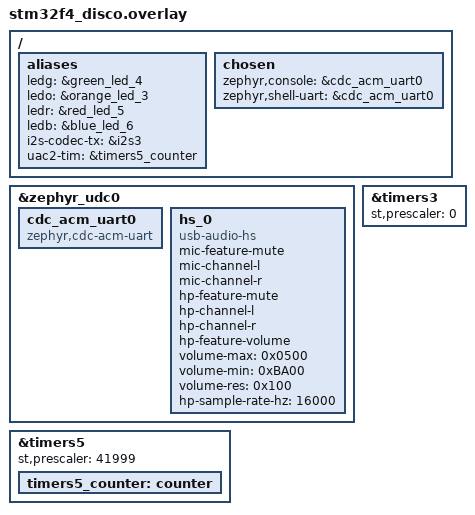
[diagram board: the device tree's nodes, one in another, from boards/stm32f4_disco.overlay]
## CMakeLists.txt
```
cmake_minimum_required(VERSION 3.20.0)

find_package(Zephyr REQUIRED HINTS $ENV{ZEPHYR_BASE})
project(audio_card_2)

target_sources(app
    PRIVATE
        src/audio.c
        src/audio_conf.c
        src/audio_feedback_counter.c
        src/audio_output_codec.c
        #src/audio_source.c
        src/audio_stream.c
        src/audio_timer.c
        src/audio_usb.c
        src/blink.c
        src/board_shell.c
        src/shell_cmd.c
        src/test_signal_generator.c
        src/usb.c
)

target_include_directories(app
    PRIVATE
        ./src
)
```

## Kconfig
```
mainmenu "Audio Card"

config APP_USE_STM32
	default y
	bool
	select USE_STM32_HAL_TIM
	select USE_STM32_HAL_GPIO
	select USE_STM32_HAL_TIM_EX
	select USE_STM32_HAL_GPIO_EX

config AUDIO_USB_SHELL
	default y
	bool


source "Kconfig.zephyr"
```

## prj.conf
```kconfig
CONFIG_BOOT_BANNER=y

CONFIG_NET_BUF=y

CONFIG_USB_DEVICE_STACK=y
CONFIG_USB_DEVICE_PRODUCT="Zephyr USB console sample"
CONFIG_USB_DEVICE_PID=0x0004
CONFIG_USB_DEVICE_INITIALIZE_AT_BOOT=n
CONFIG_USB_DEVICE_AUDIO=y
CONFIG_USBD_AUDIO2_CLASS=y

CONFIG_SERIAL=y
CONFIG_CONSOLE=y
CONFIG_UART_CONSOLE=y
CONFIG_UART_LINE_CTRL=y

CONFIG_SHELL=y
CONFIG_SHELL_BACKEND_SERIAL=y

CONFIG_PRINTK=y
CONFIG_GPIO=y

CONFIG_I2C=y
CONFIG_I2S=y
CONFIG_AUDIO=y
CONFIG_AUDIO_CODEC=y
CONFIG_AUDIO_CODEC_CS43L22=y
CONFIG_AUDIO_CODEC_SHELL=y

CONFIG_LOG=y
CONFIG_USB_DRIVER_LOG_LEVEL_ERR=y
CONFIG_USB_DEVICE_LOG_LEVEL_ERR=y

#CONFIG_NEWLIB_LIBC=n
#CONFIG_NEWLIB_LIBC_FLOAT_PRINTF=n

CONFIG_REQUIRES_FULL_LIBC=y
CONFIG_REQUIRES_FLOAT_PRINTF=y

CONFIG_CMSIS_DSP=y
CONFIG_CMSIS_DSP_COMPLEXMATH=n
CONFIG_CMSIS_DSP_TRANSFORM=n
CONFIG_CMSIS_DSP_FASTMATH=n
CONFIG_CMSIS_DSP_CONTROLLER=y

CONFIG_DEBUG=y
CONFIG_I2S_LOG_LEVEL_DBG=y
#CONFIG_LOG_DEFAULT_LEVEL=4
CONFIG_LOG_RUNTIME_FILTERING=y
CONFIG_LOG_CMDS=y
```

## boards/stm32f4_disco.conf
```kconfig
CONFIG_COUNTER=y
#CONFIG_TIMER=y
#CONFIG_COUNTER_STM32_TIMER=y
#CONFIG_USE_STM32_HAL_TIM=y
CONFIG_COUNTER_TIMER_STM32=y
CONFIG_GPIO_STM32=y
#CONFIG_USE_STM32_HAL=y
#CONFIG_USE_STM32_HAL_GPIO=y

#CONFIG_USE_STM32_HAL_TIM=y
#CONFIG_USE_STM32_HAL_TIM_EX=y
```

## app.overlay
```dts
/ {
	chosen {
		zephyr,console = &cdc_acm_uart0;
		zephyr,shell-uart = &cdc_acm_uart0;
	};

	aliases {
		i2s-codec-tx = &i2s3;
	};
};

&zephyr_udc0 {
	cdc_acm_uart0: cdc_acm_uart0 {
		compatible = "zephyr,cdc-acm-uart";
	};

	hs_0 {
		compatible = "usb-audio-hs";
		mic-feature-mute;
		mic-channel-l;
		mic-channel-r;

		hp-feature-mute;
		hp-channel-l;
		hp-channel-r;

		hp-feature-volume;
		volume-max = <0x0500>;
		volume-min = <0xBA00>;
		volume-res = <0x100>;
	};
};
```

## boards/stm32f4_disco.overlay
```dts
/ {
	aliases {
		ledg = &green_led_4;
		ledo = &orange_led_3;
		ledr = &red_led_5;
		ledb = &blue_led_6;
		i2s-codec-tx = &i2s3;
		uac2-tim = &timers5_counter;
	};

	chosen {
		zephyr,console = &cdc_acm_uart0;
		zephyr,shell-uart = &cdc_acm_uart0;
	};
};

&zephyr_udc0 {
	cdc_acm_uart0: cdc_acm_uart0 {
		compatible = "zephyr,cdc-acm-uart";
	};

	hs_0: hs_0 {
		compatible = "usb-audio-hs";
		mic-feature-mute;
		mic-channel-l;
		mic-channel-r;

		hp-feature-mute;
		hp-channel-l;
		hp-channel-r;

		hp-feature-volume;
		volume-max = <0x0500>;
		volume-min = <0xBA00>;
		volume-res = <0x100>;

		hp-sample-rate-hz = <16000>;
	};
};

&timers5 {
	status = "okay";
	st,prescaler = < 41999 >;
	timers5_counter: counter {
		status = "okay";
	};
};

&timers3 {
	status = "okay";
	st,prescaler = <0>;
};
```

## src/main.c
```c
#include <stdio.h>
#include <zephyr/device.h>
#include <zephyr/kernel.h>
#include <zephyr/devicetree.h>
#include <zephyr/sys/printk.h>
#include <zephyr/audio/codec.h>
#include <zephyr/logging/log.h>
#include <zephyr/drivers/i2s.h>
#include <zephyr/drivers/uart.h>
#include <zephyr/drivers/gpio.h>
#include <zephyr/usb/usb_device.h>
#include <zephyr/usb/class/usb_audio.h>

LOG_MODULE_REGISTER(main, LOG_LEVEL_INF);



int main(void)
{

	while(1) {
		k_msleep(1000);
	}
}
 
```

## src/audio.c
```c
#include <stdio.h>
#include <zephyr/device.h>
#include <zephyr/kernel.h>
#include <zephyr/devicetree.h>
#include <zephyr/sys/printk.h>
#include <zephyr/audio/codec.h>
#include <zephyr/logging/log.h>
#include <zephyr/drivers/i2s.h>
#include <zephyr/drivers/uart.h>
#include <zephyr/drivers/gpio.h>
#include <zephyr/usb/usb_device.h>
#include <zephyr/usb/class/usb_audio.h>

#include "audio_conf.h"

LOG_MODULE_REGISTER(audio, LOG_LEVEL_INF);

static void log_info(const struct audio_static_cfg* const cfg)
{
    LOG_INF("Sampling frequency:    %d Hz", cfg->sample_frequency);
    LOG_INF("Sample byte width:     %d bytes", cfg->sample_bytes_width);
    LOG_INF("Number of channels:    %d", cfg->number_of_channels);
    LOG_INF("Bytes per sample:      %d bytes", cfg->bytes_per_sample);
    LOG_INF("Samples per SOF:       %d", cfg->samples_per_sof);
    LOG_INF("Bytes per SOF:         %d bytes", cfg->bytes_per_sof);
}

static int init(void)
{
    log_info(audio_conf_static_get());
    return 0;
}


SYS_INIT_NAMED(
    audio,
    init,
    APPLICATION,
    0
);
 


 
```

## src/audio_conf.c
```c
#include <stdio.h>
#include <zephyr/kernel.h>

#include "audio_conf.h"



static const struct audio_static_cfg audio_static_cfg = {
    .sample_frequency = SAMPLE_FREQUENCY,
    .samples_per_sof = SAMPLES_PER_SOF,
    .sample_bytes_width = SAMPLE_BYTE_WIDTH,
    .number_of_channels = NUMBER_OF_CHANNELS,
    .bytes_per_sample = BYTES_PER_SAMPLE,
    .bytes_per_sof = BYTES_PER_SOF,
};

const struct audio_static_cfg* audio_conf_static_get(void)
{
    return &audio_static_cfg;
}
```

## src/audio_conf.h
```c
#ifndef _AUDIO_CONF_H_
#define _AUDIO_CONF_H_

#include <zephyr/devicetree.h>

//#define SAMPLE_FREQUENCY        DT_PROP(DT_NODELABEL(hs_0), hp_sample_rate_hz)
#define SAMPLE_FREQUENCY        16000
#define SAMPLE_DTYPE            int16_t
#define SAMPLE_BYTE_WIDTH       (sizeof(SAMPLE_DTYPE))
#define SAMPLE_BIT_WIDTH        (8U * SAMPLE_BYTE_WIDTH)
#define NUMBER_OF_CHANNELS      (2)
#define BYTES_PER_SAMPLE        (SAMPLE_BYTE_WIDTH * NUMBER_OF_CHANNELS)
#define SAMPLES_PER_SOF         (DIV_ROUND_UP(SAMPLE_FREQUENCY, 1000))
#define BYTES_PER_SOF           (SAMPLES_PER_SOF * BYTES_PER_SAMPLE)
#define AUDIO_STREAM_CHUNK_SIZE (size_t)(3*BYTES_PER_SOF / 2)
//#define AUDIO_STREAM_CHUNK_SIZE BYTES_PER_SOF

struct audio_static_cfg {
    uint32_t sample_frequency;
    uint32_t samples_per_sof;
    uint16_t sample_bytes_width;
    uint16_t number_of_channels;
    uint16_t bytes_per_sample;
    uint16_t bytes_per_sof;
};

const struct audio_static_cfg* audio_conf_static_get(void);


#endif
```

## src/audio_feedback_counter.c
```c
#include <zephyr/device.h>
#include <zephyr/devicetree.h>
#include <zephyr/kernel.h>
#include <zephyr/logging/log.h>
#include <zephyr/sys/reboot.h>
#include <zephyr/shell/shell.h>
#include <zephyr/init.h>

LOG_MODULE_REGISTER(audio_feedack_counter, LOG_LEVEL_INF);

#if defined(CONFIG_BOARD_STM32F4_DISCO)

//#include "stm32f4xx.h"
//#include "stm32f4xx_hal.h"
//#include "stm32f4xx_hal_tim.h"
//#include "stm32f4xx_hal_tim_ex.h"

static TIM_HandleTypeDef htim3 = {0};

static int init(void)
{
    __HAL_RCC_TIM3_CLK_ENABLE();
    __HAL_RCC_GPIOC_CLK_ENABLE();

    GPIO_InitTypeDef GPIO_InitStruct = {0};
    GPIO_InitStruct.Pin = GPIO_PIN_6;
    GPIO_InitStruct.Mode = GPIO_MODE_AF_PP;
    GPIO_InitStruct.Pull = GPIO_NOPULL;
    GPIO_InitStruct.Speed = GPIO_SPEED_FREQ_LOW;
    GPIO_InitStruct.Alternate = GPIO_AF2_TIM3;
    HAL_GPIO_Init(GPIOC, &GPIO_InitStruct);

    TIM_SlaveConfigTypeDef sSlaveConfig = {0};
    TIM_MasterConfigTypeDef sMasterConfig = {0};
    htim3.Instance = TIM3;
    htim3.Init.Prescaler = 0;
    htim3.Init.CounterMode = TIM_COUNTERMODE_UP;
    htim3.Init.Period = 65535;
    htim3.Init.ClockDivision = TIM_CLOCKDIVISION_DIV1;
    htim3.Init.AutoReloadPreload = TIM_AUTORELOAD_PRELOAD_DISABLE;
    if (HAL_TIM_Base_Init(&htim3) != HAL_OK)
    {
      //Error_Handler();
      return -1;
    }
    sSlaveConfig.SlaveMode = TIM_SLAVEMODE_EXTERNAL1;
    sSlaveConfig.InputTrigger = TIM_TS_TI1FP1;
    sSlaveConfig.TriggerPolarity = TIM_TRIGGERPOLARITY_FALLING;
    sSlaveConfig.TriggerFilter = 0;
    if (HAL_TIM_SlaveConfigSynchro(&htim3, &sSlaveConfig) != HAL_OK)
    {
      //Error_Handler();
      return -1;
    }
    sMasterConfig.MasterOutputTrigger = TIM_TRGO_RESET;
    sMasterConfig.MasterSlaveMode = TIM_MASTERSLAVEMODE_DISABLE;
    if (HAL_TIMEx_MasterConfigSynchronization(&htim3, &sMasterConfig) != HAL_OK)
    {
      //Error_Handler();
      return -1;
    }

    HAL_TIM_Base_Start(&htim3);

    return 0;
}

SYS_INIT_NAMED(
    audio_feedack_counter,
    init,
    APPLICATION,
    0
);

uint16_t audio_sof_counter(void)
{
    return (uint16_t)__HAL_TIM_GET_COUNTER(&htim3);
}

#endif
```

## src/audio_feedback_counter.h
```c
#ifndef _AUDIO_FEEDBACK_COUNTER_H_
#define _AUDIO_FEEDBACK_COUNTER_H_

#include <stdint.h>

uint16_t audio_sof_counter(void);

#endif
```

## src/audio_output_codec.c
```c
#include <stdlib.h>
#include <assert.h>
#include <zephyr/kernel.h>
#include <zephyr/device.h>
#include <zephyr/logging/log.h>
#include <zephyr/audio/codec.h>

#include "audio_output_codec.h"
#include "audio_conf.h"
#include "test_signal_generator.h"
#include "audio_stream.h"

#include "arm_math.h"

#define STACKSIZE 1024
#define PRIORITY 0

LOG_MODULE_REGISTER(audio_output_codec, LOG_LEVEL_INF);

const struct device *codec_control = DEVICE_DT_GET(DT_NODELABEL(audio_codec));
const struct device *codec_stream = DEVICE_DT_GET(DT_ALIAS(i2s_codec_tx));


K_MEM_SLAB_DEFINE_STATIC(audio_output_codec_slab, AUDIO_STREAM_CHUNK_SIZE, 4, 4);

static bool init_done = false;

bool is_audio_codec_setup(void)
{
    return init_done;
}

static int init(void)
{
    int err = 0;
    if (!device_is_ready(codec_control)) {
        LOG_ERR("%s is not ready...", codec_control->name);
        err = -1;
    }
    if (!device_is_ready(codec_stream)) {
        LOG_ERR("%s is not ready...", codec_stream->name);
        err = -1;
    }

    struct audio_codec_cfg audio_cfg = {
        .dai_route = AUDIO_ROUTE_PLAYBACK,
        .dai_type = AUDIO_DAI_TYPE_I2S,
        .dai_cfg.i2s.word_size = SAMPLE_BIT_WIDTH,
        .dai_cfg.i2s.channels = NUMBER_OF_CHANNELS,
        .dai_cfg.i2s.format = I2S_FMT_DATA_FORMAT_I2S,
        .dai_cfg.i2s.options = I2S_OPT_FRAME_CLK_MASTER,
        .dai_cfg.i2s.frame_clk_freq = SAMPLE_FREQUENCY,
        .dai_cfg.i2s.mem_slab = &audio_output_codec_slab,
        .dai_cfg.i2s.block_size = BYTES_PER_SOF
    };
    err = audio_codec_configure(codec_control, &audio_cfg);
    if (0 != err) {
        LOG_ERR("Cannot configure audio codec...");
    }

    struct i2s_config config = {
        .word_size = SAMPLE_BIT_WIDTH,
        .channels = NUMBER_OF_CHANNELS,
        .format = I2S_FMT_DATA_FORMAT_I2S,
        .options = I2S_OPT_BIT_CLK_MASTER | I2S_OPT_FRAME_CLK_MASTER,
        .frame_clk_freq = SAMPLE_FREQUENCY,
        .mem_slab = &audio_output_codec_slab,
        .block_size = BYTES_PER_SOF,
        .timeout = 0
    };
    err = i2s_configure(codec_stream, I2S_DIR_TX, &config);
    if (0 != err) {
        LOG_ERR("Cannot configure i2s device...");
    }

    if (0 == err) {
        LOG_INF("Audio output codec ready.");
        init_done = true;
    }
    return err;
}

SYS_INIT_NAMED(
    audio_codec,
    init,
    APPLICATION,
    80
);

static volatile uint32_t thread_count = 0;
static volatile uint32_t thread_step = 0;
static volatile bool print_content = false;
static void thread(void *p1, void *p2, void *p3)
{
    int ret;
    bool started = false;

    while (1) {

        k_sleep(K_MSEC(100));

        if (init_done) {
            break;
        }
    }

    while(1) {
        if (2 < audio_stream_pending_chunk_count()) {
            break;
        }
        k_sleep(K_MSEC(1));
    }

    while (1) {
        thread_step = 0;
        struct audio_chunk* audio_chunk = audio_stream_chunk_get(K_FOREVER);
        thread_step = 1;
        void* pmem = NULL;
        size_t audio_chunk_size = audio_chunk->size;
        ret = k_mem_slab_alloc(
            &audio_output_codec_slab,
            &pmem,
            K_FOREVER
        );
        thread_step = 2;
        memcpy(pmem, (void*)audio_chunk->mem, audio_chunk->size);
        audio_stream_chunk_release(audio_chunk);
        thread_step = 3;
        if (print_content) {
            print_content = false;
            int16_t* p = pmem;
            LOG_INF("Size: %d", audio_chunk_size);
            for (size_t i = 0; i < 16; i++) {
                LOG_INF("%d, %d", p[2*i], p[2*i + 1]);
            }
        }
        ret = i2s_write(codec_stream, pmem, audio_chunk_size);
        if (0 != ret) {
            //LOG_WRN("Fixing I2S state... (err %d)", ret);
            i2s_trigger(codec_stream, I2S_DIR_TX, I2S_TRIGGER_PREPARE);
            started = false;
            ret = i2s_write(codec_stream, pmem, audio_chunk_size);
            if (0 != ret) {
                k_mem_slab_free(
                    &audio_output_codec_slab,
                    pmem
                );
                LOG_ERR("Cannot write to i2s. (err %d)", ret);
                started = false;
                i2s_trigger(codec_stream, I2S_DIR_TX, I2S_TRIGGER_PREPARE);
            }
            //while(1) {
            //    if (2 < audio_stream_pending_chunk_count()) {
            //        break;
            //    }
            //    k_sleep(K_MSEC(1));
            //}

        }
        thread_step = 4;

        if (!started && 2 < k_mem_slab_num_used_get(&audio_output_codec_slab)) {
            thread_step = 5;
            ret = i2s_trigger(codec_stream, I2S_DIR_TX, I2S_TRIGGER_START);
            if (0 == ret) {
                //LOG_INF("I2S started...");
                started = true;
            }
        }
        thread_step = 6;

        thread_count++;
    }
}

K_THREAD_DEFINE(audio_output_codec_thread_id, STACKSIZE, thread, NULL, NULL, NULL,
		PRIORITY, 0, 0);


#include <zephyr/shell/shell.h>
static int cmd_get_thread_count(const struct shell *sh, size_t argc, char **argv)
{
    shell_info(sh, "Audio output codec thread count: %d, Thread step: %d", thread_count, thread_step);
    size_t free_blocks = k_mem_slab_num_free_get(&audio_output_codec_slab);
    shell_info(sh, "N available blocks: %d", free_blocks);
    print_content = true;
    return 0;
}

SHELL_CMD_REGISTER(tc_aoc, NULL, "TC", cmd_get_thread_count);
```

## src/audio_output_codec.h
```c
#ifndef _AUDIO_OUTPUT_CODEC_H_
#define _AUDIO_OUTPUT_CODEC_H_

bool is_audio_codec_setup(void);

#endif
```

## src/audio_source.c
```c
#include <zephyr/kernel.h>
#include <zephyr/logging/log.h>

#include "audio_stream.h"
#include "audio_conf.h"
#include "test_signal_generator.h"

#define STACKSIZE 1024
#define PRIORITY 4

LOG_MODULE_REGISTER(audio_source, LOG_LEVEL_INF);

static void thread(void *p1, void *p2, void *p3)
{
    while (1) {
        struct audio_chunk* audio_chunk = audio_stream_chunk_alloc(K_FOREVER);
        generate_signal_section((int16_t*)audio_chunk->mem, SAMPLES_PER_SOF);
        audio_chunk->size = BYTES_PER_SOF;
        audio_stream_chunk_commit(audio_chunk);
        //LOG_INF("New chunk created.");
        //k_msleep(1000);
    }
}

K_THREAD_DEFINE(audio_source_thread_id, STACKSIZE, thread, NULL, NULL, NULL,
		PRIORITY, 0, 0);
```

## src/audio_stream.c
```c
#include <zephyr/kernel.h>
#include <zephyr/sys/util.h>
#include <zephyr/logging/log.h>

#include "audio_stream.h"

LOG_MODULE_REGISTER(audio_stream, LOG_LEVEL_INF);

struct fifo_entry {
    void* fifo_reserved;
    struct audio_chunk data;
};

K_MEM_SLAB_DEFINE_STATIC(
    audio_stream_slab,
    sizeof(struct fifo_entry),
    5,
    4
);

K_QUEUE_DEFINE(
    audio_stream_queue
);

K_FIFO_DEFINE(
    audio_stream_fifo
);
static size_t audio_stream_fifo_entries_count = 0;
struct k_spinlock audio_stream_fifo_entries_count_lock;

static inline struct fifo_entry* audio_chunk_to_fifo_entry_ptr(struct audio_chunk* const audio_chunk) {
    return CONTAINER_OF(audio_chunk, struct fifo_entry, data);
}


struct audio_chunk* audio_stream_chunk_alloc(k_timeout_t timeout)
{
    struct fifo_entry* rv = NULL;
    int err = k_mem_slab_alloc(
        &audio_stream_slab,
        (void*)&rv,
        timeout
    );
    
    if ((0 > err) || (NULL == rv)) {
        LOG_DBG("Cannot allocate audio stream chunk. (err %d)", err);
        rv = NULL;
    }
    
    return &rv->data;
}

int audio_stream_chunk_commit(struct audio_chunk* chunk) 
{
    struct fifo_entry* entry = audio_chunk_to_fifo_entry_ptr(chunk);
    k_fifo_put(
        &audio_stream_fifo,
        (void*)entry
    );
    k_spinlock_key_t key = k_spin_lock(&audio_stream_fifo_entries_count_lock);
    audio_stream_fifo_entries_count++;
    k_spin_unlock(&audio_stream_fifo_entries_count_lock, key);
    return 0;
}

int audio_stream_chunk_abort(struct audio_chunk* chunk)
{
    return audio_stream_chunk_release(chunk);
}

struct audio_chunk* audio_stream_chunk_get(k_timeout_t timeout)
{
    return &((struct fifo_entry*) k_fifo_get(&audio_stream_fifo, timeout))->data;
}

int audio_stream_chunk_release(struct audio_chunk *chunk)
{
    struct fifo_entry* entry = audio_chunk_to_fifo_entry_ptr(chunk);
    k_mem_slab_free(
        &audio_stream_slab,
        (void*)entry
    );
    k_spinlock_key_t key = k_spin_lock(&audio_stream_fifo_entries_count_lock);
    audio_stream_fifo_entries_count--;
    k_spin_unlock(&audio_stream_fifo_entries_count_lock, key);
    return 0;
}

size_t audio_stream_pending_chunk_count(void)
{
    return audio_stream_fifo_entries_count;
}
```

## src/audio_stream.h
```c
#ifndef _AUDIO_STREAM_H_
#define _AUDIO_STREAM_H_

#include <stdint.h>

#include "audio_conf.h"

struct audio_chunk
{
    uint8_t mem[AUDIO_STREAM_CHUNK_SIZE];
    size_t size;
};

struct audio_chunk* audio_stream_chunk_alloc(k_timeout_t timeout);
int audio_stream_chunk_commit(struct audio_chunk* chunk);
int audio_stream_chunk_abort(struct audio_chunk* chunk);
struct audio_chunk* audio_stream_chunk_get(k_timeout_t timeout);
int audio_stream_chunk_release(struct audio_chunk *chunk);
size_t audio_stream_pending_chunk_count(void);

#endif 
```

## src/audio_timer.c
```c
#include <zephyr/device.h>
#include <zephyr/devicetree.h>
#include <zephyr/kernel.h>
#include <zephyr/logging/log.h>
#include <zephyr/init.h>
#include <zephyr/drivers/counter.h>

LOG_MODULE_REGISTER(audio_timer, LOG_LEVEL_INF);


const struct device *uac2_tim = DEVICE_DT_GET(DT_ALIAS(uac2_tim));


static int init(void)
{
    if (!device_is_ready(uac2_tim)) {
        LOG_ERR("UAC2 timer not ready");
        return -1;
    }
    counter_start(uac2_tim);
    return 0;
}

SYS_INIT_NAMED(
    audio_timer,
    init,
    APPLICATION,
    1
);

int audio_timer_get(uint32_t* ticks)
{
    return counter_get_value(uac2_tim, ticks);
}

int audio_timer_reset(void)
{
    return counter_reset(uac2_tim);
}
```

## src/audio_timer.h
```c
#ifndef _AUDIO_TIMER_H_
#define _AUDIO_TIMER_H_

#include <stdint.h>

int audio_timer_get(uint32_t* ticks);
int audio_timer_reset(void);

#endif
```
